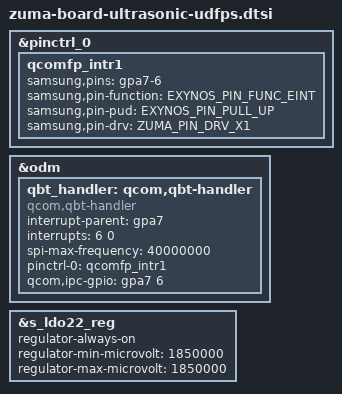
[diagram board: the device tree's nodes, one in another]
// SPDX-License-Identifier: GPL-2.0-only
/*
 * QC ultrasonic fps device tree source
 *
 * Copyright 2022 Google,LLC.
 */

&pinctrl_0 {
	qcomfp_intr1: qcomfp_intr1 {
		samsung,pins = "gpa7-6";
		samsung,pin-function = <EXYNOS_PIN_FUNC_EINT>;
		samsung,pin-pud = <EXYNOS_PIN_PULL_UP>;
		samsung,pin-drv = <ZUMA_PIN_DRV_X1>;
	};
};

&odm {
	qbt_handler: qcom,qbt-handler {
		status = "okay";
		compatible = "qcom,qbt-handler";
		interrupt-parent = <&gpa7>;
		interrupts = <6 0>;
		spi-max-frequency = <40000000>;
		pinctrl-names = "default";
		pinctrl-0 = <&qcomfp_intr1>;
		qcom,ipc-gpio = <&gpa7 6 GPIO_ACTIVE_HIGH>;
	};
};

&s_ldo22_reg {
	regulator-always-on;
	regulator-min-microvolt = <1850000>;
	regulator-max-microvolt = <1850000>;
};
